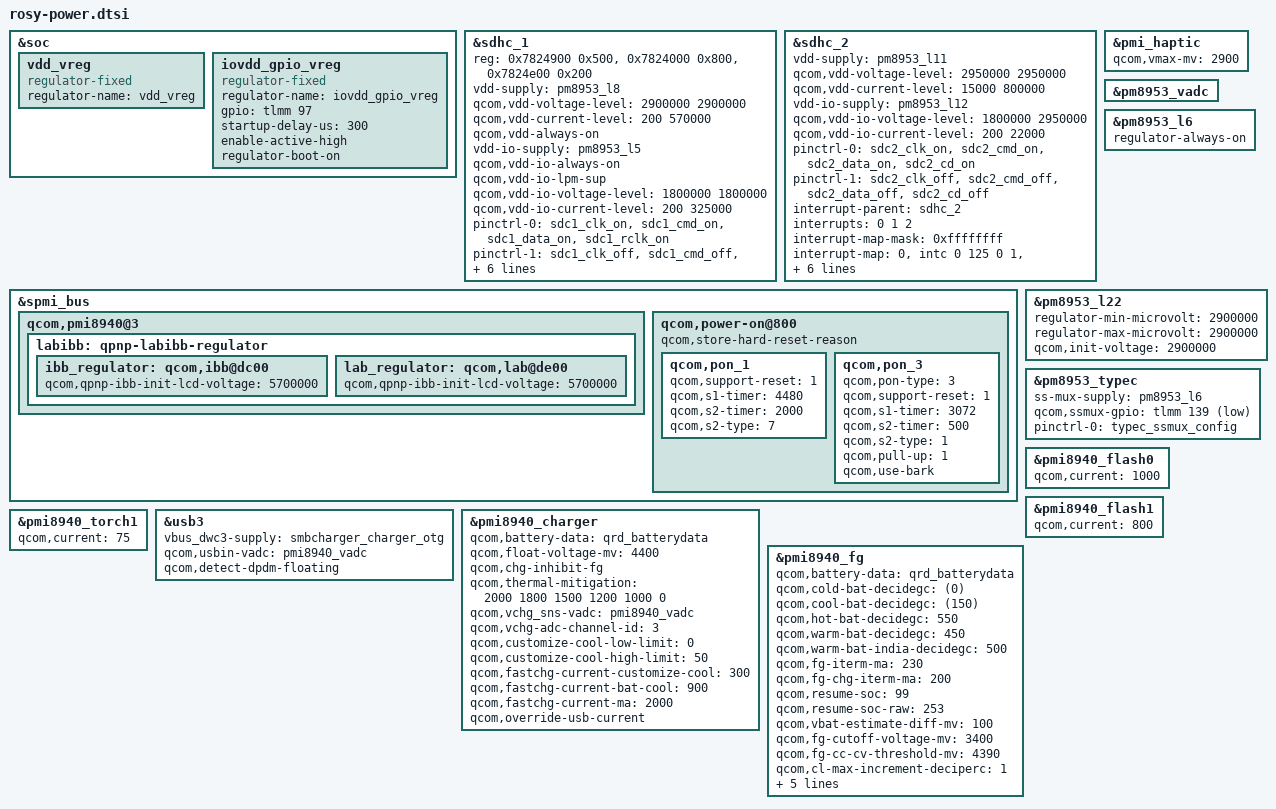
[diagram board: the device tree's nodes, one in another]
&soc {
	vdd_vreg: vdd_vreg {
		compatible = "regulator-fixed";
		regulator-name = "vdd_vreg";
		status = "ok";
	};

	iovdd_gpio_vreg: iovdd_gpio_vreg {
		compatible = "regulator-fixed";
		regulator-name="iovdd_gpio_vreg";
		gpio = <&tlmm 97 0>; /* iovdd - ldo6 */
		startup-delay-us = <300>;
		enable-active-high;
		regulator-boot-on;
		status = "ok";
	};
};

&sdhc_1 {
	/* device core power supply */
	reg = <0x7824900 0x500>, <0x7824000 0x800>, <0x7824e00 0x200>;
	reg-names = "hc_mem", "core_mem", "cmdq_mem";
	vdd-supply = <&pm8953_l8>;
	qcom,vdd-voltage-level = <2900000 2900000>;
	qcom,vdd-current-level = <200 570000>;
	qcom,vdd-always-on;

	/* device communication power supply */
	vdd-io-supply = <&pm8953_l5>;
	qcom,vdd-io-always-on;
	qcom,vdd-io-lpm-sup;
	qcom,vdd-io-voltage-level = <1800000 1800000>;
	qcom,vdd-io-current-level = <200 325000>;

	pinctrl-names = "active", "sleep";
	pinctrl-0 = <&sdc1_clk_on &sdc1_cmd_on &sdc1_data_on &sdc1_rclk_on>;
	pinctrl-1 = <&sdc1_clk_off &sdc1_cmd_off &sdc1_data_off &sdc1_rclk_off>;

	qcom,clk-rates = <400000 20000000 25000000 50000000 100000000 192000000
			384000000>;
	qcom,nonremovable;
	qcom,bus-speed-mode = "HS400_1p8v", "HS200_1p8v", "DDR_1p8v";
	status = "ok";
};

&sdhc_2 {
	/* device core power supply */
	vdd-supply = <&pm8953_l11>;
	qcom,vdd-voltage-level = <2950000 2950000>;
	qcom,vdd-current-level = <15000 800000>;

	/* device communication power supply */
	vdd-io-supply = <&pm8953_l12>;
	qcom,vdd-io-voltage-level = <1800000 2950000>;
	qcom,vdd-io-current-level = <200 22000>;

	pinctrl-names = "active", "sleep";
	pinctrl-0 = <&sdc2_clk_on &sdc2_cmd_on &sdc2_data_on &sdc2_cd_on>;
	pinctrl-1 = <&sdc2_clk_off &sdc2_cmd_off &sdc2_data_off &sdc2_cd_off>;

	#address-cells = <0>;
	interrupt-parent = <&sdhc_2>;
	interrupts = <0 1 2>;
	#interrupt-cells = <1>;
	interrupt-map-mask = <0xffffffff>;
	interrupt-map = <0 &intc 0 125 0
			1 &intc 0 221 0
			2 &tlmm 133 0>;
	interrupt-names = "hc_irq", "pwr_irq", "status_irq";
	cd-gpios = <&tlmm 133 0x0>;

	qcom,clk-rates = <400000 20000000 25000000 50000000 100000000
			200000000>;
	qcom,bus-speed-mode = "SDR12", "SDR25", "SDR50", "DDR50", "SDR104";
	status = "ok";
};

&spmi_bus {

	qcom,pmi8940@3 {
		labibb: qpnp-labibb-regulator {
			ibb_regulator: qcom,ibb@dc00 {
				/delete-property/ qcom,qpnp-ibb-use-default-voltage;
				qcom,qpnp-ibb-init-lcd-voltage = <5700000>;
			};

			lab_regulator: qcom,lab@de00 {
				/delete-property/ qcom,qpnp-ibb-use-default-voltage;
				qcom,qpnp-ibb-init-lcd-voltage = <5700000>;
			};
		};
	};

	qcom,power-on@800 {
		qcom,store-hard-reset-reason;

		qcom,pon_1 {
			qcom,support-reset = <1>;
			qcom,s1-timer = <4480>;
			qcom,s2-timer = <2000>;
			qcom,s2-type = <7>;
		};

		qcom,pon_3 {
			qcom,pon-type = <3>;
			qcom,support-reset = <1>;
			qcom,s1-timer = <3072>;
			qcom,s2-timer = <500>;
			qcom,s2-type = <1>;
			qcom,pull-up = <1>;
			qcom,use-bark;
		};
	};
};

&pmi_haptic {
	qcom,vmax-mv = <2900>;
};

&pm8953_vadc {
	/delete-node/ chan@11;
};

&pm8953_l6 {
	regulator-always-on;
};

&pm8953_l22 {
	regulator-min-microvolt = <2900000>;
	regulator-max-microvolt = <2900000>;
	qcom,init-voltage = <2900000>;
};

&pm8953_typec {
	ss-mux-supply = <&pm8953_l6>;
	qcom,ssmux-gpio = <&tlmm 139 GPIO_ACTIVE_LOW>;
	pinctrl-names = "default";
	pinctrl-0 = <&typec_ssmux_config>;
};

&pmi8940_flash0 {
	qcom,current = <1000>;
};

&pmi8940_flash1 {
	qcom,current = <800>;
};

&pmi8940_torch1 {
	qcom,current = <75>;
};

&usb3 {
	vbus_dwc3-supply = <&smbcharger_charger_otg>;
	qcom,usbin-vadc = <&pmi8940_vadc>;
	qcom,detect-dpdm-floating;
};

&pmi8940_charger {
	qcom,battery-data = <&qrd_batterydata>;
	qcom,float-voltage-mv = <4400>;
	qcom,chg-inhibit-fg;
	qcom,thermal-mitigation = <2000 1800 1500 1200 1000 0>;
	qcom,vchg_sns-vadc = <&pmi8940_vadc>;
	qcom,vchg-adc-channel-id = <3>;
	qcom,customize-cool-low-limit = <0>;
	qcom,customize-cool-high-limit = <50>;
	qcom,fastchg-current-customize-cool = <300>;
	qcom,fastchg-current-bat-cool = <900>;
	qcom,fastchg-current-ma = <2000>;
	qcom,override-usb-current;
	status = "okay";
};

&pmi8940_fg {
	qcom,battery-data = <&qrd_batterydata>;
	qcom,cold-bat-decidegc = <(0)>;
	qcom,cool-bat-decidegc = <(150)>;
	qcom,hot-bat-decidegc = <550>;
	qcom,warm-bat-decidegc = <450>;
	qcom,warm-bat-india-decidegc = <500>;
	qcom,fg-iterm-ma = <230>;
	qcom,fg-chg-iterm-ma = <200>;
	qcom,resume-soc = <99>;
	qcom,resume-soc-raw = <253>;
	qcom,vbat-estimate-diff-mv = <100>;
	qcom,fg-cutoff-voltage-mv = <3400>;
	qcom,fg-cc-cv-threshold-mv = <4390>;
	qcom,cl-max-increment-deciperc = <1>;
	qcom,cl-max-decrement-deciperc = <1>;
	qcom,fg-delta-soc = <2>;
	qcom,bad-battery-detection-enable;
	qcom,hold-soc-while-full;
	qcom,thermal-coefficients = [DA 86 F0 50 08 3C];
};
